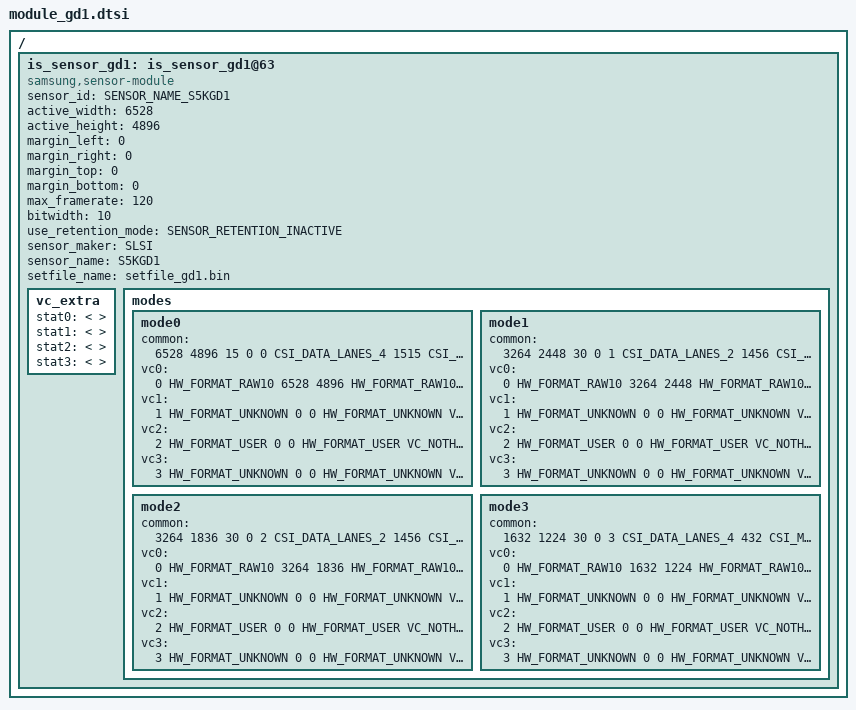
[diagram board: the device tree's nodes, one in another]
/*
 * SAMSUNG EXYNOSxxxx board camera device tree source
 *
 * Copyright (c) 2019 Samsung Electronics Co., Ltd.
 *		http://www.samsung.com
 *
 * This program is free software; you can redistribute it and/or modify
 * it under the terms of the GNU General Public License version 2 as
 * published by the Free Software Foundation.
 */

#include <dt-bindings/camera/exynos_is_dt.h>

/ {
	fragment@camera {
		target-path = "/";
		__overlay__ {
			is_sensor_gd1: is_sensor_gd1@63 {
				compatible = "samsung,sensor-module";

				/* common */
				sensor_id = <SENSOR_NAME_S5KGD1>;
				active_width = <6528>;
				active_height = <4896>;
				margin_left = <0>;
				margin_right = <0>;
				margin_top = <0>;
				margin_bottom = <0>;
				max_framerate = <120>;
				bitwidth = <10>;
				use_retention_mode = <SENSOR_RETENTION_INACTIVE>;
				sensor_maker = "SLSI";
				sensor_name = "S5KGD1";
				setfile_name = "setfile_gd1.bin";

				status = "okay";

				vc_extra {
					/* ex) statX = <stat_type, sensor_mode, max_width, max_height, max_element> */
					stat0 = </* not avaliable */>;	/* VC_BUF_DATA_TYPE_SENSOR_STAT1 */
					stat1 = </* not avaliable */>;	/* VC_BUF_DATA_TYPE_GENERAL_STAT1 */
					stat2 = </* not avaliable */>;	/* VC_BUF_DATA_TYPE_SENSOR_STAT2 */
					stat3 = </* not avaliable */>;	/* VC_BUF_DATA_TYPE_GENERAL_STAT2 */
				};

				/* sensor modes */
				modes {
						/* common = <width, height, fps, settle, mode, lane, speed, interleave, pd_mode> */
						/* vcX = <map, hwformat, width, height, hwformat, type, width, height> */
					mode0 {
						common = <6528 4896 15 0 0 CSI_DATA_LANES_4 1515 CSI_MODE_VC_DT LRTE_DISABLE PD_NONE EX_NONE>;
						vc0 = </* in */ 0 HW_FORMAT_RAW10 6528 4896	/* out */ HW_FORMAT_RAW10 VC_NOTHING 6528 4896>;
						vc1 = </* in */ 1 HW_FORMAT_UNKNOWN 0 0		/* out */ HW_FORMAT_UNKNOWN VC_NOTHING 0 0>;
						vc2 = </* in */ 2 HW_FORMAT_USER 0 0		/* out */ HW_FORMAT_USER VC_NOTHING 0 0>;
						vc3 = </* in */ 3 HW_FORMAT_UNKNOWN 0 0		/* out */ HW_FORMAT_UNKNOWN VC_NOTHING 0 0>;
					};
					mode1 {
						common = <3264 2448 30 0 1 CSI_DATA_LANES_2 1456 CSI_MODE_VC_DT LRTE_DISABLE PD_NONE EX_NONE>;
						vc0 = </* in */ 0 HW_FORMAT_RAW10 3264 2448	/* out */ HW_FORMAT_RAW10 VC_NOTHING 3264 2448>;
						vc1 = </* in */ 1 HW_FORMAT_UNKNOWN 0 0		/* out */ HW_FORMAT_UNKNOWN VC_NOTHING 0 0>;
						vc2 = </* in */ 2 HW_FORMAT_USER 0 0		/* out */ HW_FORMAT_USER VC_NOTHING 0 0>;
						vc3 = </* in */ 3 HW_FORMAT_UNKNOWN 0 0		/* out */ HW_FORMAT_UNKNOWN VC_NOTHING 0 0>;
					};
					mode2 {
						common = <3264 1836 30 0 2 CSI_DATA_LANES_2 1456 CSI_MODE_VC_DT LRTE_DISABLE PD_NONE EX_NONE>;
						vc0 = </* in */ 0 HW_FORMAT_RAW10 3264 1836	/* out */ HW_FORMAT_RAW10 VC_NOTHING 3264 1836>;
						vc1 = </* in */ 1 HW_FORMAT_UNKNOWN 0 0		/* out */ HW_FORMAT_UNKNOWN VC_NOTHING 0 0>;
						vc2 = </* in */ 2 HW_FORMAT_USER 0 0		/* out */ HW_FORMAT_USER VC_NOTHING 0 0>;
						vc3 = </* in */ 3 HW_FORMAT_UNKNOWN 0 0		/* out */ HW_FORMAT_UNKNOWN VC_NOTHING 0 0>;
					};
					mode3 {
						common = <1632 1224 30 0 3 CSI_DATA_LANES_4 432 CSI_MODE_VC_DT LRTE_DISABLE PD_NONE EX_NONE>;
						vc0 = </* in */ 0 HW_FORMAT_RAW10 1632 1224	/* out */ HW_FORMAT_RAW10 VC_NOTHING 1632 1224>;
						vc1 = </* in */ 1 HW_FORMAT_UNKNOWN 0 0		/* out */ HW_FORMAT_UNKNOWN VC_NOTHING 0 0>;
						vc2 = </* in */ 2 HW_FORMAT_USER 0 0		/* out */ HW_FORMAT_USER VC_NOTHING 0 0>;
						vc3 = </* in */ 3 HW_FORMAT_UNKNOWN 0 0		/* out */ HW_FORMAT_UNKNOWN VC_NOTHING 0 0>;
					};
				};
			};
		}; /* end of __overlay__ */
	}; /* end of fragment */
}; /* end of root */
